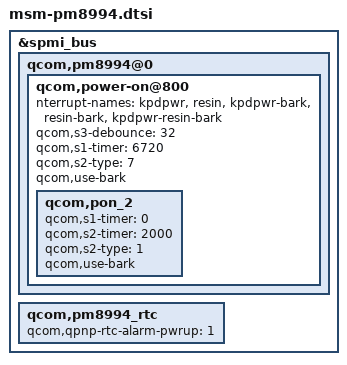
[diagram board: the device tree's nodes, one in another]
&spmi_bus {
	qcom,pm8994@0 {
		qcom,power-on@800 {
			nterrupt-names = "kpdpwr", "resin", "kpdpwr-bark", "resin-bark", "kpdpwr-resin-bark";
			qcom,s3-debounce = <32>;
			qcom,s1-timer = <6720>;
			qcom,s2-type = <7>;
			qcom,use-bark;
			
				qcom,pon_2 {
				qcom,s1-timer = <0>;
				qcom,s2-timer = <2000>;
				qcom,s2-type = <1>;
				qcom,use-bark;
			};
		};
	};

	qcom,pm8994_rtc {
		qcom,qpnp-rtc-alarm-pwrup = <1>;
	};
};
